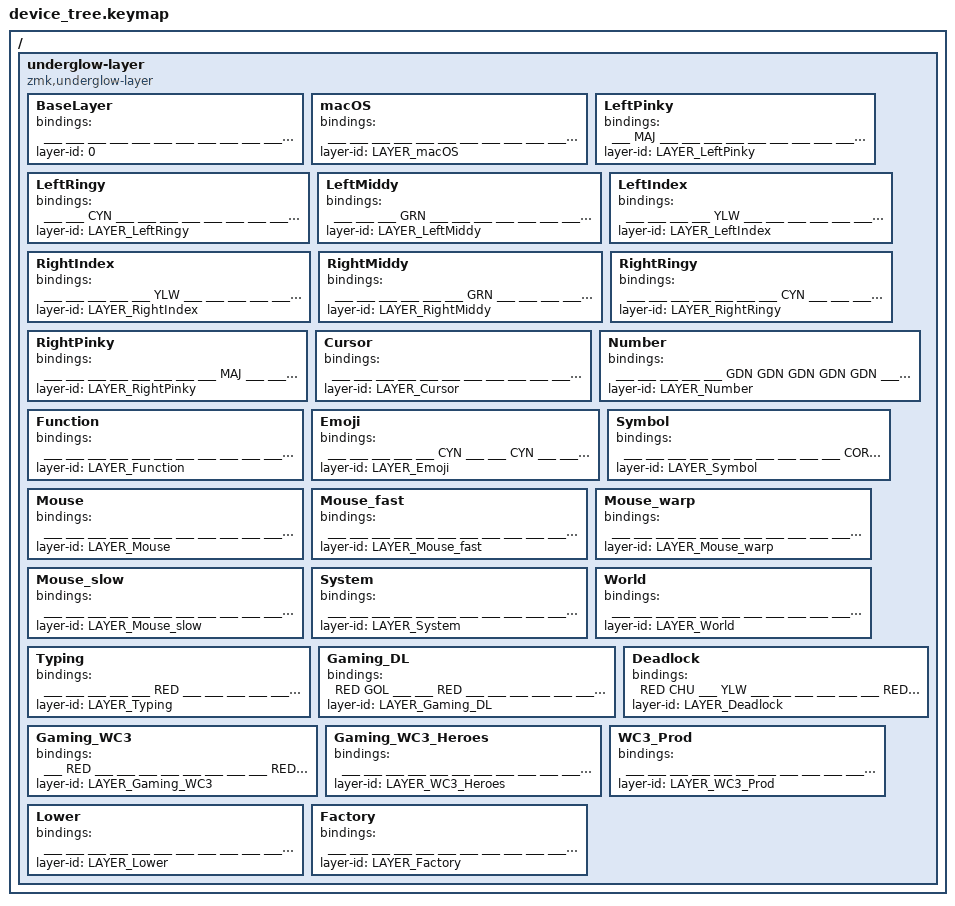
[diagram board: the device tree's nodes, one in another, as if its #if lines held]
//////////////////////////////////////////////////////////////////////////////
//
// Per-key RGB indicators for layers & mods -- requires PR36 beta firmware:
// override "EXPERIMENTAL_RGB_LAYER" to "y" in Advanced Configuration and
// select "community.pr36.per-key-rgb" from the drop-down menu located at
// Glove80 Layout Editor > Settings > Advanced Settings > Firmware Version
//
// - https://github.com/moergo-sc/zmk/pull/36
// - https://github.com/moergo-sc/zmk/pull/30
// - https://github.com/zmkfirmware/zmk/pull/2752
// - https://dev.glove80.com/#/layout/user/c42ac32d-dc0d-4160-9ee3-fd0fc15f1725
//
//////////////////////////////////////////////////////////////////////////////

#if __has_include(<dt-bindings/zmk/rgb_colors.h>)
  //
  // Color definitions with conflict guard to prevent
  // accidental redefinition of common abbreviations.
  //
  #if defined(RED) || defined(RED_RGB) || \
      defined(COR) || defined(COR_RGB) || \
      defined(ORN) || defined(ORN_RGB) || \
      defined(GDN) || defined(GDN_RGB) || \
      defined(GOL) || defined(GOL_RGB) || \
      defined(YLW) || defined(YLW_RGB) || \
      defined(CHU) || defined(CHU_RGB) || \
      defined(GRN) || defined(GRN_RGB) || \
      defined(SPG) || defined(SPG_RGB) || \
      defined(CYN) || defined(CYN_RGB) || \
      defined(AZU) || defined(AZU_RGB) || \
      defined(TEA) || defined(TEA_RGB) || \
      defined(TUR) || defined(TUR_RGB) || \
      defined(BLU) || defined(BLU_RGB) || \
      defined(PUR) || defined(PUR_RGB) || \
      defined(MAJ) || defined(MAJ_RGB) || \
      defined(PNK) || defined(PNK_RGB) || \
      defined(WHT) || defined(WHT_RGB) || \
      defined(BLK) || defined(BLK_RGB) || \
      defined(___) || \
      defined(DUG) || defined(DUG_RGB) || \
      defined(LAC) || defined(LAC_RGB) || \
      defined(BSL) || defined(BNL) || defined(BCL) || \
      defined(SSL) || defined(SNL) || defined(SCL) || \
      defined(FST) || defined(WRP) || defined(SLO)
  #error "Naming conflict: 3-letter color abbreviation already defined!"
  #endif

  //
  // color definitions from QMK
  // https://github.com/qmk/qmk_firmware/blob/master/quantum/color.h
  //
  #define RED_RGB 0xFF0000 // #FF0000 RED      => RED (red)
  #define COR_RGB 0xFF7C4D // #FF7C4D CORAL    => COR (coral)
  #define ORN_RGB 0xFF8000 // #FF8000 ORANGE   => ORN (ornj)
  #define GDN_RGB 0xD9A521 // #D9A521 GOLDNROD => GDN (gold'nrod)
  #define GOL_RGB 0xFFD900 // #FFD900 GOLD     => GOL (gold)
  #define YLW_RGB 0xFFFF00 // #FFFF00 YELLOW   => YLW (yellow)
  #define CHU_RGB 0x80FF00 // #80FF00 CHARTRSE => CHU (chartreuse)
  #define GRN_RGB 0x00FF00 // #00FF00 GREEN    => GRN (green)
  #define SPG_RGB 0x00FF80 // #00FF80 SPRINGRN => SPG (spring green)
  #define CYN_RGB 0x00FFFF // #00FFFF CYAN     => CYN (sigh-an)
  #define AZU_RGB 0x99F5FF // #99F5FF AZURE    => AZU (a-zur)
  #define TEA_RGB 0x008080 // #008080 TEAL     => TEA (teel)
  #define TUR_RGB 0x476E6A // #476E6A TURQUOIS => TUR (turquoise)
  #define BLU_RGB 0x0000FF // #0000FF BLUE     => BLU (bloo)
  #define PUR_RGB 0x7A00FF // #7A00FF PURPLE   => PUR (purp)
  #define MAJ_RGB 0xFF00FF // #FF00FF MAGENTA  => MAJ (mah-jenta)
  #define PNK_RGB 0xFF80BF // #FF80BF PINK     => PNK (pink)
  #define WHT_RGB 0xFFFFFF // #FFFFFF WHITE    => WHT (white)
  #define BLK_RGB 0x000000 // #000000 BLACK    => BLK (blak)

  //
  // color definitions from MoErgo
  // https://github.com/moergo-sc/zmk/blob/aca523dfce9b6447ffd19d833b791d44f1f286de/app/src/rgb_underglow.c#L259-L265
  //
  #define DUG_RGB 0x00ff68 // #00ff68 DULL_GRN => DUG (dull green)
  #define LAC_RGB 0x6b1fce // #6b1fce LILAC    => LAC (lilac)

  //
  // underglow for the colors above
  //
  #define RED &ug RED_RGB
  #define COR &ug COR_RGB
  #define ORN &ug ORN_RGB
  #define GDN &ug GDN_RGB
  #define GOL &ug GOL_RGB
  #define YLW &ug YLW_RGB
  #define CHU &ug CHU_RGB
  #define GRN &ug GRN_RGB
  #define SPG &ug SPG_RGB
  #define CYN &ug CYN_RGB
  #define AZU &ug AZU_RGB
  #define TEA &ug TEA_RGB
  #define TUR &ug TUR_RGB
  #define BLU &ug BLU_RGB
  #define PUR &ug PUR_RGB
  #define MAJ &ug MAJ_RGB
  #define PNK &ug PNK_RGB
  #define WHT &ug WHT_RGB
  #define BLK &ug BLK_RGB
  #define ___ &ug BLK_RGB
  #define DUG &ug DUG_RGB
  #define LAC &ug LAC_RGB

  //
  // underglow for keyboard locks on the Base layer
  //
  #define BSL &ug_sl LAC_RGB WHT_RGB // ScrollLock COLOR_OFF COLOR_ON
  #define BNL &ug_nl LAC_RGB WHT_RGB // NumLock    COLOR_OFF COLOR_ON
  #define BCL &ug_cl BLK_RGB WHT_RGB // CapsLock   COLOR_OFF COLOR_ON

  //
  // underglow for keyboard locks on the System layer
  //
  #define SSL &ug_sl BLK_RGB WHT_RGB // ScrollLock COLOR_OFF COLOR_ON
  #define SNL &ug_nl BLK_RGB WHT_RGB // NumLock    COLOR_OFF COLOR_ON
  #define SCL &ug_cl BLK_RGB WHT_RGB // CapsLock   COLOR_OFF COLOR_ON

  //
  // colors for mouse speed scaling in Mouse layers
  //
  #define FST GOL
  #define SLO PNK
  #define WRP CHU

  // ==== PER-KEY-RGB <section begins> ====
  / {
    underglow-layer {
      compatible  = "zmk,underglow-layer";

      /*
      Template {
        bindings = <
          ___ ___ ___ ___ ___                                             ___ ___ ___ ___ ___
          ___ ___ ___ ___ ___ ___                                     ___ ___ ___ ___ ___ ___
          ___ ___ ___ ___ ___ ___                                     ___ ___ ___ ___ ___ ___
          ___ ___ ___ ___ ___ ___                                     ___ ___ ___ ___ ___ ___
          ___ ___ ___ ___ ___ ___     ___ ___ ___     ___ ___ ___     ___ ___ ___ ___ ___ ___
          ___ ___ ___ ___ ___         ___ ___ ___     ___ ___ ___         ___ ___ ___ ___ ___
        >;
        layer-id = <LAYER_Template>;
      };
      */

      BaseLayer {
        bindings = <
          ___ ___ ___ ___ ___                                             ___ ___ ___ ___ ___
          ___ ___ ___ ___ ___ ___                                     ___ ___ ___ ___ ___ ___
          ___ ___ ___ ___ ___ ___                                     ___ ___ ___ ___ ___ ___
          ___ MAJ CYN GRN YLW ___                                     ___ YLW GRN CYN MAJ ___
          YLW ___ ___ ___ ___ ___     LAC COR ___     ___ COR LAC     ___ ___ ___ ___ ___ YLW
          ___ ___ ___ ___ LAC         BSL BNL BCL     ___ LAC LAC         LAC ___ ___ ___ ___
        >;
        layer-id = <0>;
      };

      #ifdef LAYER_macOS
      macOS {
        bindings = <
          ___ ___ ___ ___ ___                                             ___ ___ ___ ___ ___
          ___ ___ ___ ___ ___ ___                                     ___ ___ ___ ___ ___ ___
          ___ ___ ___ ___ ___ ___                                     ___ ___ ___ ___ ___ ___
          ___ GRN CYN MAJ YLW ___                                     ___ YLW MAJ CYN GRN ___
          YLW ___ ___ ___ ___ ___     LAC COR ___     ___ COR LAC     ___ ___ ___ ___ ___ YLW
          RED RED ___ ___ LAC         BSL BNL BCL     ___ LAC LAC         LAC ___ ___ RED RED
        >;
        layer-id = <LAYER_macOS>;
      };
      #endif

      #ifdef LAYER_LeftPinky
      LeftPinky {
        bindings = <
          ___ MAJ ___ ___ ___                                             ___ ___ ___ ___ ___
          ___ ___ ___ ___ ___ ___                                     ___ ___ ___ ___ ___ ___
          ___ ___ ___ ___ ___ ___                                     ___ ___ ___ ___ ___ ___
          ___ MAJ CYN GRN YLW ___                                     ___ YLW GRN CYN MAJ ___
          YLW ___ ___ ___ ___ ___     LAC COR ___     ___ COR LAC     ___ ___ ___ ___ ___ YLW
          ___ ___ ___ ___ LAC         BSL BNL BCL     ___ LAC LAC         LAC ___ ___ ___ ___
        >;
        layer-id = <LAYER_LeftPinky>;
      };
      #endif

      #ifdef LAYER_LeftRingy
      LeftRingy {
        bindings = <
          ___ ___ CYN ___ ___                                             ___ ___ ___ ___ ___
          ___ ___ ___ ___ ___ ___                                     ___ ___ ___ ___ ___ ___
          ___ ___ ___ ___ ___ ___                                     ___ ___ ___ ___ ___ ___
          ___ MAJ CYN GRN YLW ___                                     ___ YLW GRN CYN MAJ ___
          YLW ___ ___ ___ ___ ___     LAC COR ___     ___ COR LAC     ___ ___ ___ ___ ___ YLW
          ___ ___ ___ ___ LAC         BSL BNL BCL     ___ LAC LAC         LAC ___ ___ ___ ___
        >;
        layer-id = <LAYER_LeftRingy>;
      };
      #endif

      #ifdef LAYER_LeftMiddy
      LeftMiddy {
        bindings = <
          ___ ___ ___ GRN ___                                             ___ ___ ___ ___ ___
          ___ ___ ___ ___ ___ ___                                     ___ ___ ___ ___ ___ ___
          ___ ___ ___ ___ ___ ___                                     ___ ___ ___ ___ ___ ___
          ___ MAJ CYN GRN YLW ___                                     ___ YLW GRN CYN MAJ ___
          YLW ___ ___ ___ ___ ___     LAC COR ___     ___ COR LAC     ___ ___ ___ ___ ___ YLW
          ___ ___ ___ ___ LAC         BSL BNL BCL     ___ LAC LAC         LAC ___ ___ ___ ___
        >;
        layer-id = <LAYER_LeftMiddy>;
      };
      #endif

      #ifdef LAYER_LeftIndex
      LeftIndex {
        bindings = <
          ___ ___ ___ ___ YLW                                             ___ ___ ___ ___ ___
          ___ ___ ___ ___ ___ ___                                     ___ ___ ___ ___ ___ ___
          ___ ___ ___ ___ ___ ___                                     ___ ___ ___ ___ ___ ___
          ___ MAJ CYN GRN YLW ___                                     ___ YLW GRN CYN MAJ ___
          YLW ___ ___ ___ ___ ___     LAC COR ___     ___ COR LAC     ___ ___ ___ ___ ___ YLW
          ___ ___ ___ ___ LAC         BSL BNL BCL     ___ LAC LAC         LAC ___ ___ ___ ___
        >;
        layer-id = <LAYER_LeftIndex>;
      };
      #endif

      #ifdef LAYER_RightIndex
      RightIndex {
        bindings = <
          ___ ___ ___ ___ ___                                             YLW ___ ___ ___ ___
          ___ ___ ___ ___ ___ ___                                     ___ ___ ___ ___ ___ ___
          ___ ___ ___ ___ ___ ___                                     ___ ___ ___ ___ ___ ___
          ___ MAJ CYN GRN YLW ___                                     ___ YLW GRN CYN MAJ ___
          YLW ___ ___ ___ ___ ___     LAC COR ___     ___ COR LAC     ___ ___ ___ ___ ___ YLW
          ___ ___ ___ ___ LAC         BSL BNL BCL     ___ LAC LAC         LAC ___ ___ ___ ___
        >;
        layer-id = <LAYER_RightIndex>;
      };
      #endif

      #ifdef LAYER_RightMiddy
      RightMiddy {
        bindings = <
          ___ ___ ___ ___ ___                                             ___ GRN ___ ___ ___
          ___ ___ ___ ___ ___ ___                                     ___ ___ ___ ___ ___ ___
          ___ ___ ___ ___ ___ ___                                     ___ ___ ___ ___ ___ ___
          ___ MAJ CYN GRN YLW ___                                     ___ YLW GRN CYN MAJ ___
          YLW ___ ___ ___ ___ ___     LAC COR ___     ___ COR LAC     ___ ___ ___ ___ ___ YLW
          ___ ___ ___ ___ LAC         BSL BNL BCL     ___ LAC LAC         LAC ___ ___ ___ ___
        >;
        layer-id = <LAYER_RightMiddy>;
      };
      #endif

      #ifdef LAYER_RightRingy
      RightRingy {
        bindings = <
          ___ ___ ___ ___ ___                                             ___ ___ CYN ___ ___
          ___ ___ ___ ___ ___ ___                                     ___ ___ ___ ___ ___ ___
          ___ ___ ___ ___ ___ ___                                     ___ ___ ___ ___ ___ ___
          ___ MAJ CYN GRN YLW ___                                     ___ YLW GRN CYN MAJ ___
          YLW ___ ___ ___ ___ ___     LAC COR ___     ___ COR LAC     ___ ___ ___ ___ ___ YLW
          ___ ___ ___ ___ LAC         BSL BNL BCL     ___ LAC LAC         LAC ___ ___ ___ ___
        >;
        layer-id = <LAYER_RightRingy>;
      };
      #endif

      #ifdef LAYER_RightPinky
      RightPinky {
        bindings = <
          ___ ___ ___ ___ ___                                             ___ ___ ___ MAJ ___
          ___ ___ ___ ___ ___ ___                                     ___ ___ ___ ___ ___ ___
          ___ ___ ___ ___ ___ ___                                     ___ ___ ___ ___ ___ ___
          ___ MAJ CYN GRN YLW ___                                     ___ YLW GRN CYN MAJ ___
          YLW ___ ___ ___ ___ ___     LAC COR ___     ___ COR LAC     ___ ___ ___ ___ ___ YLW
          ___ ___ ___ ___ LAC         BSL BNL BCL     ___ LAC LAC         LAC ___ ___ ___ ___
        >;
        layer-id = <LAYER_RightPinky>;
      };
      #endif

      #ifdef LAYER_Cursor
      Cursor {
        bindings = <
          ___ ___ ___ ___ ___                                             ___ ___ ___ ___ ___
          ___ COR COR COR COR ___                                     ___ ___ ___ ___ ___ ___
          ___ COR COR COR COR GDN                                     GDN COR PUR PUR COR ___
          YLW MAJ CYN GRN YLW GDN                                     GDN AZU AZU AZU AZU YLW
          PNK SPG SPG SPG PUR GDN     COR COR ___     SPG SPG SPG     GDN AZU AZU AZU AZU PNK
          PNK PUR PUR PUR PUR         RED ___ ___     SPG SPG SPG         PUR PUR PUR PUR PNK
        >;
        layer-id = <LAYER_Cursor>;
      };
      #endif

      #ifdef LAYER_Number
      Number {
        bindings = <
          ___ ___ ___ ___ ___                                             GDN GDN GDN GDN GDN
          ___ COR COR COR COR ___                                     TEA SPG SPG SPG SPG SPG
          ___ COR COR COR COR GOL                                     TEA GOL GOL GOL SPG SPG
          YLW MAJ CYN GRN YLW TEA                                     TEA GOL GOL GOL SPG SPG
          GDN SPG SPG SPG PUR GDN     ___ ___ ___     SPG SPG SPG     TEA GOL GOL GOL SPG SPG
          TEA PUR PUR PUR PUR         ___ RED ___     SPG SPG GOL         SPG SPG SPG SPG SPG
        >;
        layer-id = <LAYER_Number>;
      };
      #endif

      #ifdef LAYER_Function
      Function {
        bindings = <
          ___ ___ ___ ___ ___                                             ___ ___ ___ ___ ___
          ___ COR COR COR COR ___                                     AZU AZU AZU AZU AZU AZU
          ___ COR COR COR COR GDN                                     GDN PNK PNK PNK PNK PNK
          YLW MAJ CYN GRN YLW GDN                                     GDN PNK PNK PNK PNK PNK
          ___ SPG SPG SPG PUR GDN     RED ___ ___     AZU BLU BLU     GDN PNK PNK PNK PNK PNK
          ___ PUR PUR PUR PUR         ___ ___ ___     AZU AZU AZU         CHU CHU CHU CHU CHU
        >;
        layer-id = <LAYER_Function>;
      };
      #endif

      #ifdef LAYER_Emoji
      Emoji {
        bindings = <
          ___ ___ ___ ___ ___                                             CYN ___ ___ CYN ___
          ___ ___ ___ ___ ___ ___                                     ___ CYN ___ ___ CYN ___
          ___ ___ ___ ___ ___ ___                                     ___ ___ ___ ___ ___ ___
          ___ GDN PNK SPG AZU ___                                     CYN ___ ___ ___ ___ CYN
          ___ ___ ___ ___ ___ ___     ___ ___ ___     ___ ___ ___     ___ CYN ___ ___ CYN ___
          ___ ___ ___ ___ RED         YLW ___ ___     ___ ___ ___         ___ CYN CYN ___ ___
        >;
        layer-id = <LAYER_Emoji>;
      };
      #endif

      #ifdef LAYER_Symbol
      Symbol {
        bindings = <
          ___ ___ ___ ___ ___                                             ___ ___ ___ ___ ___
          COR PNK AZU AZU CHU CHU                                     ___ ___ ___ ___ ___ ___
          PUR AZU AZU AZU AZU GDN                                     CHU COR COR COR COR ___
          GDN GDN SPG BLU GDN GDN                                     CHU COR COR COR COR ___
          PUR SPG SPG SPG SPG GDN     PUR CHU GDN     ___ ___ ___     CHU PNK PNK PNK PUR YLW
          COR BLU PNK PNK BLU         GDN GDN GDN     ___ ___ RED         YLW GRN CYN MAJ ___
        >;
        layer-id = <LAYER_Symbol>;
      };
      #endif

      #ifdef LAYER_Mouse
      Mouse {
        bindings = <
          ___ ___ ___ ___ ___                                             ___ ___ ___ ___ ___
          ___ ___ ___ ___ ___ ___                                     ___ ___ ___ ___ ___ ___
          ___ ___ SPG AZU SPG ___                                     GDN GDN GDN GDN GDN ___
          ___ SPG AZU AZU AZU SPG                                     SPG FST WRP SLO PUR SPG
          ___ SPG SLO WRP FST SPG     GDN PUR GDN     BLU BLU BLU     SPG AZU AZU AZU AZU SPG
          ___ ___ BLU BLU BLU         GDN GDN GDN     ___ RED ___         YLW GRN CYN MAJ ___
        >;
        layer-id = <LAYER_Mouse>;
      };
      #endif

      #ifdef LAYER_Mouse_fast
      Mouse_fast {
        bindings = <
          ___ ___ ___ ___ ___                                             ___ ___ ___ ___ ___
          ___ ___ ___ ___ ___ ___                                     ___ ___ ___ ___ ___ ___
          ___ ___ SPG FST SPG ___                                     GDN GDN GDN GDN GDN ___
          ___ SPG FST FST FST SPG                                     SPG FST WRP SLO PUR GDN
          ___ SPG FST FST FST SPG     GDN PUR GDN     BLU BLU BLU     SPG FST FST FST FST GDN
          ___ ___ BLU BLU BLU         GDN GDN GDN     ___ RED ___         YLW GRN CYN MAJ ___
        >;
        layer-id = <LAYER_Mouse_fast>;
      };
      #endif

      #ifdef LAYER_Mouse_warp
      Mouse_warp {
        bindings = <
          ___ ___ ___ ___ ___                                             ___ ___ ___ ___ ___
          ___ ___ ___ ___ ___ ___                                     ___ ___ ___ ___ ___ ___
          ___ ___ SPG WRP SPG ___                                     GDN GDN GDN GDN GDN ___
          ___ SPG WRP WRP WRP SPG                                     SPG FST WRP SLO PUR GDN
          ___ SPG WRP WRP WRP SPG     GDN PUR GDN     BLU BLU BLU     SPG WRP WRP WRP WRP GDN
          ___ ___ BLU BLU BLU         GDN GDN GDN     ___ RED ___         YLW GRN CYN MAJ ___
        >;
        layer-id = <LAYER_Mouse_warp>;
      };
      #endif

      #ifdef LAYER_Mouse_slow
      Mouse_slow {
        bindings = <
          ___ ___ ___ ___ ___                                             ___ ___ ___ ___ ___
          ___ ___ ___ ___ ___ ___                                     ___ ___ ___ ___ ___ ___
          ___ ___ SPG SLO SPG ___                                     GDN GDN GDN GDN GDN ___
          ___ SPG SLO SLO SLO SPG                                     SPG FST WRP SLO PUR GDN
          ___ SPG SLO SLO SLO SPG     GDN PUR GDN     BLU BLU BLU     SPG SLO SLO SLO SLO GDN
          ___ ___ BLU BLU BLU         GDN GDN GDN     ___ RED ___         YLW GRN CYN MAJ PUR
        >;
        layer-id = <LAYER_Mouse_slow>;
      };
      #endif

      #ifdef LAYER_System
      System {
        bindings = <
          ___ ___ ___ ___ ___                                             ___ ___ ___ ___ ___
          ___ ___ ___ ___ ___ ___                                     ___ ___ ___ ___ ___ ___
          ___ PNK AZU SPG GDN COR                                     COR GDN SPG AZU PNK ___
          ___ PNK AZU SPG GDN COR                                     COR GDN SPG AZU PNK ___
          ___ ___ BLU BLU BLU COR     PUR PUR PUR     ___ ORN RED     COR SSL SNL SCL PUR PUR
          ___ ___ ___ ___ ORN         SSL SNL SCL     BLU BLU BLU         YLW GRN CYN MAJ PUR
        >;
        layer-id = <LAYER_System>;
      };
      #endif

      #ifdef LAYER_World
      World {
        bindings = <
          ___ ___ ___ ___ ___                                             ___ ___ ___ ___ ___
          ___ ___ ___ ___ ___ ___                                     ___ ___ ___ ___ ___ ___
          ___ SPG AZU AZU AZU ___                                     ___ ___ CYN CYN ___ ___
          AZU AZU AZU AZU AZU ___                                     ___ YLW GRN GRN YLW ___
          AZU AZU SPG SPG AZU ___     ___ ___ ___     ___ ___ ___     ___ ___ ___ ___ ___ ___
          SPG SPG SPG SPG SPG         ___ ___ ___     ___ ___ ___         RED ___ ___ ___ ___
        >;
        layer-id = <LAYER_World>;
      };
      #endif

      #ifdef LAYER_Typing
      Typing {
        bindings = <
          ___ ___ ___ ___ ___                                             RED ___ ___ ___ ___
          ___ ___ ___ ___ ___ ___                                     RED ___ ___ ___ ___ ___
          ___ ___ ___ ___ ___ ___                                     ___ ___ ___ ___ ___ ___
          ___ ___ ___ ___ ___ ___                                     ___ ___ ___ ___ ___ ___
          ___ ___ ___ ___ ___ ___     ___ ___ ___     ___ ___ ___     ___ ___ ___ ___ ___ ___
          ___ ___ ___ ___ ___         ___ ___ ___     ___ ___ ___         ___ ___ ___ ___ ___
        >;
        layer-id = <LAYER_Typing>;
      };
      #endif

      #ifdef LAYER_Gaming_DL
      Gaming_DL {
        bindings = <
          RED GOL ___ ___ RED                                             ___ ___ ___ ___ ___
          ___ ___ ___ ___ ___ RED                                     ___ ___ ___ ___ ___ ___
          ___ ___ ORN ___ ___ RED                                     ___ ___ ___ ___ ___ ___
          ___ BLU MAJ ___ ORN ORN                                     ___ ___ ___ ___ ___ ___
          ___ WHT ___ ___ ___ BLU     CHU ___ ___     ___ ___ ___     ___ ___ ___ ___ ___ ___
          ___ BLU BLU MAJ BLU         WHT ___ MAJ     ___ ___ ___         ___ ___ ___ ___ ___
        >;
        layer-id = <LAYER_Gaming_DL>;
      };
      #endif

      #ifdef LAYER_Deadlock
      Deadlock {
        bindings = <
          RED CHU ___ YLW ___                                             ___ ___ ___ ___ ___
          RED ___ YLW YLW YLW ___                                     ___ ___ ___ ___ ___ ___
          RED WHT ___ ___ ___ WHT                                     ___ ___ ___ ___ ___ ___
          ___ ___ CYN ___ CYN CYN                                     ___ ___ ___ ___ ___ ___
          ___ WHT CYN ___ CYN ___     ___ ___ ___     ___ ___ ___     ___ ___ ___ ___ ___ ___
          ___ ___ ___ ___ ___         ___ ___ ___     ___ ___ ___         ___ ___ ___ ___ ___
        >;
        layer-id = <LAYER_Deadlock>;
      };
      #endif

      #ifdef LAYER_Gaming_WC3
      Gaming_WC3 {
        bindings = <
          ___ RED ___ ___ ___                                             ___ ___ ___ ___ ___
          RED ___ ___ ___ ___ ___                                     ___ ___ ___ ___ ___ ___
          ___ ___ ___ ___ ___ ___                                     ___ ___ ___ ___ ___ ___
          ___ GRN ORN RED BLU MAJ                                     ___ ___ ___ ___ ___ ___
          RED WHT ___ ___ ___ ___     COR AZU LAC     ___ ___ ___     ___ ___ ___ ___ ___ ___
          PUR ___ ___ ___ ___         ___ ___ GOL     ___ ___ ___         ___ ___ ___ ___ ___
        >;
        layer-id = <LAYER_Gaming_WC3>;
      };
      #endif

      #ifdef LAYER_WC3_Heroes
      Gaming_WC3_Heroes {
        bindings = <
          ___ ___ ___ ___ ___                                             ___ ___ ___ ___ ___
          ___ ___ LAC LAC LAC LAC                                     ___ ___ ___ ___ ___ ___
          ___ ___ ___ RED ___ ___                                     ___ ___ ___ ___ ___ ___
          ___ ___ AZU AZU ORN ___                                     ___ ___ ___ ___ ___ ___
          ___ WHT AZU AZU ORN ___     ___ ___ ___     ___ ___ ___     ___ ___ ___ ___ ___ ___
          ___ ___ AZU AZU ORN         ___ ___ ___     ___ ___ ___         ___ ___ ___ ___ ___
        >;
        layer-id = <LAYER_WC3_Heroes>;
      };
      #endif

      #ifdef LAYER_WC3_Prod
      WC3_Prod {
        bindings = <
          ___ ___ ___ ___ ___                                             ___ ___ ___ ___ ___
          ___ ___ ___ ___ ___ ___                                     ___ ___ ___ ___ ___ ___
          ___ ___ ___ ___ ___ ___                                     ___ ___ ___ ___ ___ ___
          ___ ___ COR COR COR PNK                                     ___ ___ ___ ___ ___ ___
          RED WHT ___ ___ ___ ___     ___ ___ ___     ___ ___ ___     ___ ___ ___ ___ ___ ___
          PUR AZU ___ ___ ___         ___ ___ ___     ___ ___ ___         ___ ___ ___ ___ ___
        >;
        layer-id = <LAYER_WC3_Prod>;
      };
      #endif

      #ifdef LAYER_Lower
      Lower {
        bindings = <
          ___ ___ ___ ___ ___                                             ___ ___ ___ ___ ___
          ___ ___ ___ ___ ___ ___                                     ___ ___ ___ ___ ___ ___
          ___ GOL GOL GOL GOL GOL                                     GOL GOL GOL GOL GOL ___
          ___ MAJ CYN GRN YLW SPG                                     SPG YLW GRN CYN MAJ ___
          ___ SPG SPG SPG SPG SPG     RED ___ BLU     BLU ___ RED     SPG PNK PNK SPG PNK ___
          ___ ___ ___ ___ RED         RED RED COR     COR RED RED         RED ___ ___ ___ ___
        >;
        layer-id = <LAYER_Lower>;
      };
      #endif

      #ifdef LAYER_Factory
      Factory {
        bindings = <
          ___ ___ ___ ___ ___                                             ___ ___ ___ ___ ___
          ___ ___ ___ ___ ___ ___                                     ___ ___ ___ ___ ___ ___
          ___ ___ ___ ___ ___ ___                                     ___ ___ ___ ___ ___ ___
          ___ ___ ___ ___ ___ ___                                     ___ ___ ___ ___ ___ ___
          ___ ___ ___ ___ ___ ___     ___ ___ RED     ___ ___ ___     ___ ___ ___ ___ ___ ___
          RED ___ ___ ___ ___         ___ ___ ___     ___ ___ ___         ___ ___ ___ ___ ___
        >;
        layer-id = <LAYER_Factory>;
      };
      #endif

    };
  };
  // ==== PER-KEY-RGB <section ends> =====

  #undef RED
  #undef RED_RGB
  #undef COR
  #undef COR_RGB
  #undef ORN
  #undef ORN_RGB
  #undef GDN
  #undef GDN_RGB
  #undef GOL
  #undef GOL_RGB
  #undef YLW
  #undef YLW_RGB
  #undef CHU
  #undef CHU_RGB
  #undef GRN
  #undef GRN_RGB
  #undef SPG
  #undef SPG_RGB
  #undef CYN
  #undef CYN_RGB
  #undef AZU
  #undef AZU_RGB
  #undef TEA
  #undef TEA_RGB
  #undef TUR
  #undef TUR_RGB
  #undef BLU
  #undef BLU_RGB
  #undef PUR
  #undef PUR_RGB
  #undef MAJ
  #undef MAJ_RGB
  #undef PNK
  #undef PNK_RGB
  #undef WHT
  #undef WHT_RGB
  #undef BLK
  #undef BLK_RGB
  #undef ___
  #undef DUG
  #undef DUG_RGB
  #undef LAC
  #undef LAC_RGB

  #undef BSL
  #undef BNL
  #undef BCL

  #undef SSL
  #undef SNL
  #undef SCL

  #undef FST
  #undef WRP
  #undef SLO
#endif

